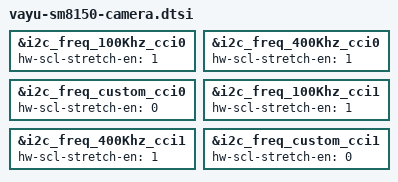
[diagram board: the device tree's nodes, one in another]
/* Copyright (c) 2021, The Linux Foundation. All rights reserved.
*  Copyright (c) 2021, Jebaitedneko <Jebaitedneko@gmail.com>.
*
* This program is free software; you can redistribute it and/or modify
* it under the terms of the GNU General Public License version 2 and
* only version 2 as published by the Free Software Foundation.
*
* This program is distributed in the hope that it will be useful,
* but WITHOUT ANY WARRANTY; without even the implied warranty of
* MERCHANTABILITY or FITNESS FOR A PARTICULAR PURPOSE.  See the
* GNU General Public License for more details.
*/

/* sm8150-camera */

&i2c_freq_100Khz_cci0 {

	hw-scl-stretch-en = <1>;
};

&i2c_freq_400Khz_cci0 {

	hw-scl-stretch-en = <1>;
};

&i2c_freq_custom_cci0 {

	hw-scl-stretch-en = <0>;
};

&i2c_freq_100Khz_cci1 {

	hw-scl-stretch-en = <1>;
};

&i2c_freq_400Khz_cci1 {

	hw-scl-stretch-en = <1>;
};

&i2c_freq_custom_cci1 {

	hw-scl-stretch-en = <0>;
};
